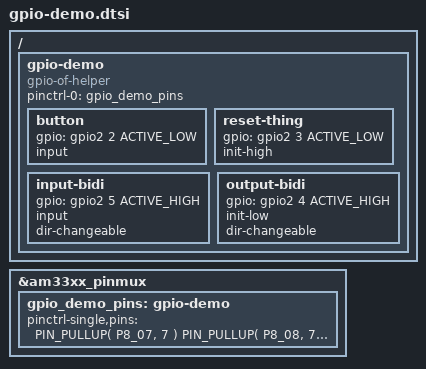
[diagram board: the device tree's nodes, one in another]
#include "bone/black.h"
#include "gpio.h"

// IMPORTANT: if you have cape-universal enabled (which is the default),
// make sure your kernel version is one of the ones listed here or newer:
//	https://pastebin.com/2w2XtJBP

// disable conflicting cape-universal nodes.
USES_PIN( P8_07 );  // gpio 2.02 / button
USES_PIN( P8_08 );  // gpio 2.03 / reset-thing
USES_PIN( P8_09 );  // gpio 2.05 / input-bidi
USES_PIN( P8_10 );  // gpio 2.04 / output-bidi


// A udev rule along these lines is recommended, to create symlinks in /dev/gpio:
//
//	SUBSYSTEM=="subsystem", KERNEL=="gpio", ACTION=="add", \
//		RUN+="/bin/mkdir -p /dev/gpio"
//
//	SUBSYSTEM=="gpio", ACTION=="add", TEST=="value", ATTR{label}!="sysfs", \
//		RUN+="/bin/ln -sT '/sys/class/gpio/%k' /dev/gpio/%s{label}"

/ {
	// If you want to use multiple overlays that do gpio configuration, be
	// sure that each uses a different device tree node!
	gpio-demo {
		compatible = "gpio-of-helper";

		// It is usually not *strictly* required to perform pinmux for
		// GPIOs since this is typically their default, but it's good
		// practice to do it anyway since:
		// 1. it makes *sure* the pinmux is right
		// 2. you can configure internal pull-up/down
		// 3. it lets the kernel know the pins are in use
		pinctrl-names = "default";
		pinctrl-0 = <&gpio_demo_pins>;

		// Note that gpio numbers for each pin can be found in the
		// comments in include/bone/black.h

		// input only, active-low; connect button between pin and gnd.
		// declaring the gpio as ACTIVE_LOW means the value reads as 1
		// when the button is pressed.
		button {
			gpio = <&gpio2 2 ACTIVE_LOW>;  // P8.07
			input;
		};

		// output only, active-low, initially high
		reset-thing {
			gpio = <&gpio2 3 ACTIVE_LOW>;  // P8.08
			init-high;
		};

		// note: ACTIVE_LOW inverts the meaning of the value, but it
		// does not invert the meaning of "init-low" / "init-high" !


		// bidirectional, initially input
		input-bidi {
			gpio = <&gpio2 5 ACTIVE_HIGH>;  // P8.09
			input;
			dir-changeable;
		};

		// bidirectional, initially output, initially low
		output-bidi {
			gpio = <&gpio2 4 ACTIVE_HIGH>;  // P8.10
			init-low;
			dir-changeable;
		};
	};
};

&am33xx_pinmux {
	gpio_demo_pins: gpio-demo {
		pinctrl-single,pins = <
			PIN_PULLUP( P8_07, 7 )  // gpio 2.02 / button
			PIN_PULLUP( P8_08, 7 )  // gpio 2.03 / reset-thing
			PIN_PULLUP( P8_09, 7 )  // gpio 2.05 / input-bidi
			PIN_PULLUP( P8_10, 7 )  // gpio 2.04 / output-bidi
		>;
	};
};
